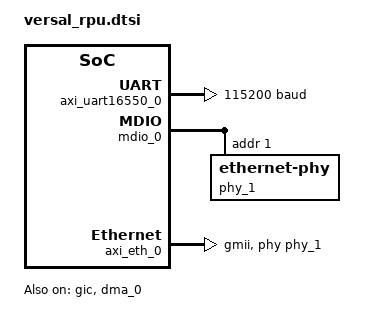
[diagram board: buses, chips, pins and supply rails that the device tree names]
/*
 * Copyright (c) 2019 Stephanos Ioannidis <root@stephanos.io>
 *
 * SPDX-License-Identifier: Apache-2.0
 */

#include <arm/xilinx/versal.dtsi>

/ {
	cpus {
		#address-cells = <1>;
		#size-cells = <0>;

		cpu@0 {
			device_type = "cpu";
			compatible = "arm,cortex-r5f";
			reg = <0>;
		};
	};

	soc {

		interrupt-parent = <&gic>;

		gic: interrupt-controller@f9000000 {
			compatible = "arm,gic-v1", "arm,gic";
			reg = <0xf9000000 0x1000>,
					<0xf9001000 0x1000>;
			interrupt-controller;
			#interrupt-cells = <4>;
			status = "okay";
		};

		axi_uart16550_0: uart@800c0000 {
			status = "okay";
			compatible = "ns16550";
			clock-frequency = <100000000>;
			current-speed = <115200>;
			interrupt-parent = <&gic>;
			interrupts = <GIC_SPI 91 IRQ_TYPE_EDGE IRQ_DEFAULT_PRIORITY>; 
			reg = <0x800c0000 0x10000>;
			reg-shift= <0x2>;
		};

		dma_0: dma@800e0000 {
			status = "okay";
			#dma-cells = <1>;
			clock-frequency = <100000000>;
            clock-names = "s_axi_lite_aclk";
			compatible = "xlnx,eth-dma";
			interrupt-parent = <&gic>;
			interrupts = <GIC_SPI 87 IRQ_TYPE_EDGE IRQ_DEFAULT_PRIORITY>,
							<GIC_SPI 88 IRQ_TYPE_EDGE IRQ_DEFAULT_PRIORITY>;
			reg = <0x800e0000 0x10000>;
			xlnx,addrwidth = <0x20>;
			xlnx,include-dre;
			dma-channels = <0x02>;
			xlnx,num-queues = <0x1>;
		};
		
		mdio_0: mdio {
			#address-cells = <1>;
			#size-cells = <0>;
			status = "okay";
			compatible = "xlnx,axi-ethernet-7.2-mdio";
			clock-frequency = <50000000>;
			phy_1: phy@1 {
				compatible = "ethernet-phy";
				reg = <0x01>;
				status = "okay";
				fixed-link = "1000BASE-T Full-Duplex";
			};           
		};

		axi_eth_0: ethernet@80040000 {
			status = "okay";
			reg = <0x80000000 0x40000>;
			compatible = "xlnx,axi-ethernet-7.2";
			local-mac-address = [00 0a 35 00 00 00];
			axistream-connected = <&dma_0>;
			axistream-control-connected = <&dma_0>;
			phy-handle = <&phy_1>;
			device_type = "network";
			clock-frequency = <100000000>;
			interrupt-parent = <&gic>;
			interrupts = <GIC_SPI 89 IRQ_TYPE_EDGE IRQ_DEFAULT_PRIORITY>;
			phy-mode = "gmii";
			xlnx,rxcsum = <0x2>; /* full checksum */
			xlnx,txcsum = <0x2>; /* full checksum */
					
		};
	};
};
